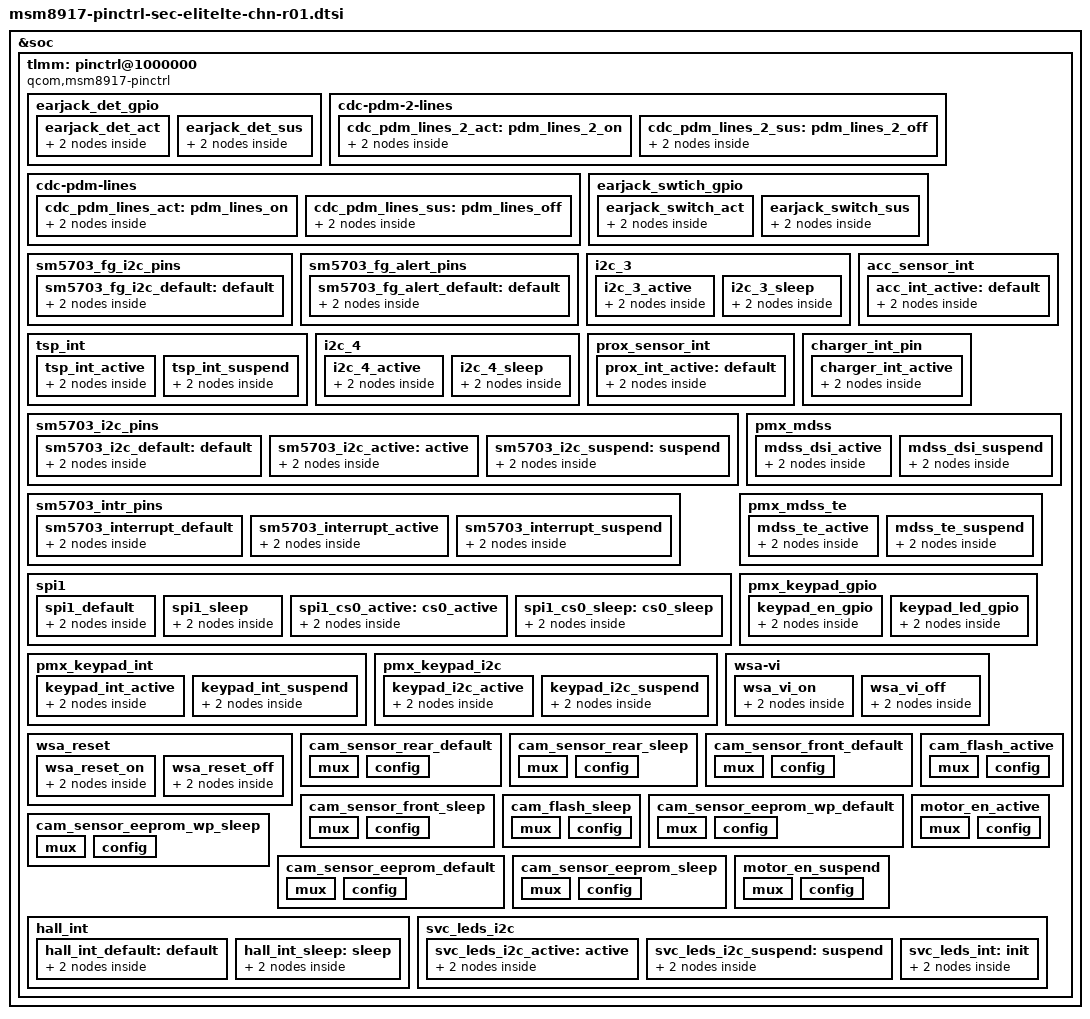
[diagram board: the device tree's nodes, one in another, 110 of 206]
/*
 * Copyright (c) 2015, The Linux Foundation. All rights reserved.
 *
 * This program is free software; you can redistribute it and/or modify
 * it under the terms of the GNU General Public License version 2 and
 * only version 2 as published by the Free Software Foundation.
 *
 * This program is distributed in the hope that it will be useful,
 * but WITHOUT ANY WARRANTY; without even the implied warranty of
 * MERCHANTABILITY or FITNESS FOR A PARTICULAR PURPOSE.  See the
 * GNU General Public License for more details.
 */

#include "../../qcom/msm8917-pinctrl.dtsi"

&soc {
	tlmm: pinctrl@1000000 {
		compatible = "qcom,msm8917-pinctrl";
		reg = <0x1000000 0x300000>;
		interrupts = <0 208 0>;
		gpio-controller;
		#gpio-cells = <2>;
		interrupt-controller;
		#interrupt-cells = <2>;

		earjack_det_gpio {
				earjack_det_act: earjack_det_act {
					mux {
						pins = "gpio61";
						function = "gpio";
					};

					config {
						pins = "gpio61";
						drive-strength = <2>;
						bias-disable;
					};
				};
				earjack_det_sus: earjack_det_sus {
					mux {
						pins = "gpio61";
						function = "gpio";
					};

					config {
						pins = "gpio61";
						drive-strength = <2>;
						bias-disable;
					};
				};
		};

		cdc-pdm-2-lines {
			cdc_pdm_lines_2_act: pdm_lines_2_on {
				mux {
					pins = "gpio70", "gpio71", "gpio72";
					function = "cdc_pdm0";
				};

				config {
					pins = "gpio70", "gpio71", "gpio72";
					drive-strength = <8>;
					bias-pull-down;
				};
			};

			cdc_pdm_lines_2_sus: pdm_lines_2_off {
				mux {
					pins = "gpio70", "gpio71", "gpio72";
					function = "cdc_pdm0";
				};

				config {
					pins = "gpio70", "gpio71", "gpio72";
					drive-strength = <2>;
					bias-pull-down;
				};
			};
		};

		cdc-pdm-lines {
			cdc_pdm_lines_act: pdm_lines_on {
				mux {
					pins = "gpio69", "gpio73", "gpio74";
					function = "cdc_pdm0";
				};

				config {
					pins = "gpio69", "gpio73", "gpio74";
					drive-strength = <8>;
					bias-pull-down;
				};
			};
			cdc_pdm_lines_sus: pdm_lines_off {
				mux {
					pins = "gpio69", "gpio73", "gpio74";
					function = "cdc_pdm0";
				};

				config {
					pins = "gpio69", "gpio73", "gpio74";
					drive-strength = <2>;
					bias-pull-down;
				};
			};
		};

		earjack_swtich_gpio {
				earjack_switch_act: earjack_switch_act {
					mux {
						pins = "gpio93";
						function = "gpio";
					};

					config {
						pins = "gpio93";
						drive-strength = <2>;
						bias-disable;
					};
				};
				earjack_switch_sus: earjack_switch_sus {
					mux {
						pins = "gpio93";
						function = "gpio";
					};

					config {
						pins = "gpio93";
						drive-strength = <2>;
						bias-disable;
					};
				};
		};


		/* Fuelgauge I2C pins */
		sm5703_fg_i2c_pins {

			sm5703_fg_i2c_default: default {
				/* default state */
				mux {
					pins = "gpio6", "gpio7";
					function = "gpio";
				};

				config {
					pins = "gpio6", "gpio7";
					drive-strength = <2>;
					bias-disable;
				};
			};

		};

		/* Fuelgauge alert pin */
                sm5703_fg_alert_pins {

                        sm5703_fg_alert_default: default {
                                /* default state */
                                mux {
                                        pins = "gpio63";
                                        function = "gpio";
                                };

                                config {
                                        pins = "gpio63";
                                        drive-strength = <2>;
                                        bias-disable;
                                };
                        };

                };

		/* pingrp for tsp - start */
		i2c_3 {
			i2c_3_active: i2c_3_active {
				/* active state */
				mux {
					pins = "gpio10", "gpio11";
					function = "blsp_i2c3";
				};

				config {
					pins = "gpio10", "gpio11";
					drive-strength = <2>;
					bias-disable;
				};
			};

			i2c_3_sleep: i2c_3_sleep {
				/* suspended state */
				mux {
					pins = "gpio10", "gpio11";
					function = "blsp_i2c3";
				};

				config {
					pins = "gpio10", "gpio11";
					drive-strength = <2>;
					bias-disable;
				};
			};
		};

		tsp_int {
			tsp_int_active: tsp_int_active {
				mux {
					pins = "gpio65";
					function = "gpio";
				};

				config {
					pins = "gpio65";
					drive-strength = <2>;
					bias-disable;
				};
			};
			tsp_int_suspend: tsp_int_suspend {
				mux {
					pins = "gpio65";
					function = "gpio";
				};

				config {
					pins = "gpio65";
					drive-strength = <2>;
					bias-disable;
				};
			};
		};

		/* pingrp for sensor - start */
		i2c_4 {
			i2c_4_active: i2c_4_active {
				/* active state */
				mux {
					pins = "gpio14", "gpio15";
					function = "blsp_i2c4";
				};

				config {
					pins = "gpio14", "gpio15";
					drive-strength = <2>;
					bias-disable;
				};
			};

			i2c_4_sleep: i2c_4_sleep {
				/* suspended state */
				mux {
					pins = "gpio14", "gpio15";
					function = "blsp_i2c4";
				};

				config {
					pins = "gpio14", "gpio15";
					drive-strength = <2>;
					bias-disable;
				};
			};
		};

		acc_sensor_int {
			acc_int_active: default {
				mux {
					pins = "gpio42";
					function = "gpio";
				};

				config {
					pins = "gpio42";
					drive-strength = <2>;
					bias-pull-down;
				};
			};
		};
		prox_sensor_int {
			prox_int_active: default {
				mux {
					pins = "gpio43";
					function = "gpio";
				};

				config {
					pins = "gpio43";
					drive-strength = <2>;
					bias-disable;
				};
			};
		};
		/* pingrp for sensor - end */

			/* MUIC - SM5703 */
		sm5703_i2c_pins {
			sm5703_i2c_default: default {
				/* default state*/
				mux {
					pins = "gpio16", "gpio17"; /* SDA, SCL */
                        		function = "gpio";
				};
				config {
					pins = "gpio16", "gpio17";
					drive-strength = <2>;
					bias-disable;
				};
			};
	
			sm5703_i2c_active: active {
				/*active state*/
				 mux {
                                        pins = "gpio16", "gpio17"; /* SDA, SCL */
                                        function = "gpio";
                                };
                                config {
                                        pins = "gpio16", "gpio17";
                                        drive-strength = <2>;
                                        bias-disable;
                                };
		
			};
			sm5703_i2c_suspend: suspend {
				/*suspend state*/
				 mux {
                                        pins = "gpio16", "gpio17"; /* SDA, SCL */
                                        function = "gpio";
                                };
                                config {
                                        pins = "gpio16", "gpio17";
                                        drive-strength = <2>;
                                        bias-disable;
                                };

			};
		};

		sm5703_intr_pins {
			sm5703_interrupt_default: sm5703_interrupt_default {
				/*default state*/
				mux {
					pins = "gpio28";
					function = "gpio";
				};
				config {
					pins = "gpio28";
					drive-strength = <2>;
					bias-disable;
				};
			};

			sm5703_interrupt_active: sm5703_interrupt_active {
				/*active state*/
				mux {
                                        pins = "gpio28";
                                        function = "gpio";
                                };
                                config {
                                        pins = "gpio28";
                                        drive-strength = <2>;
                                        bias-disable;
                                };
		
			};
			sm5703_interrupt_suspend: sm5703_interrupt_suspend {
				/*suspend state*/
				 mux {
                                        pins = "gpio28";
                                        function = "gpio";
                                };
                                config {
                                        pins = "gpio28";
                                        drive-strength = <2>;
                                        bias-disable;
                                };
			};
		};

		charger_int_pin {
			qcom,num-grp-pins = <1>;
			qcom,pin-func = <0>;
			label = "charger_int_gpio";
			charger_int_active: charger_int_active {
			    mux {
				    pins = "gpio35";
				    function = "gpio";
			    };
			    config {
				    pins = "gpio35";
				    drive-strength = <2>;
				    bias_disable;
			    };
		    };
		};

		spi1 {
			spi1_default: spi1_default {
				/* active state */
				mux {
					/* MOSI, MISO, CLK */
					pins = "gpio0", "gpio1", "gpio3";
					function = "blsp_spi1";
				};

				config {
					pins = "gpio0", "gpio1", "gpio3";
					drive-strength = <2>; /* 12 MA */
					bias-disable = <0>; /* No PULL */
					input-low;
				};
			};

			spi1_sleep: spi1_sleep {
				/* suspended state */
				mux {
					/* MOSI, MISO, CLK */
					pins = "gpio0", "gpio1", "gpio3";
					function = "gpio";
				};

				config {
					pins = "gpio0", "gpio1", "gpio3";
					drive-strength = <2>; /* 2 MA */
					bias-pull-down; /* PULL Down */
					input-low;
				};
			};

			spi1_cs0_active: cs0_active {
				/* CS */
				mux {
					pins = "gpio2";
					function = "blsp_spi1";
				};

				config {
					pins = "gpio2";
					drive-strength = <2>;
					bias-disable = <0>;
				};
			};

			spi1_cs0_sleep: cs0_sleep {
				/* CS */
				mux {
					pins = "gpio2";
					function = "gpio";
				};

				config {
					pins = "gpio2";
					drive-strength = <2>;
					bias-disable = <0>;
				};
			};
		};
		
		pmx_mdss: pmx_mdss {
			/* ON_CELL panel control LCD  power */
			mdss_dsi_active: mdss_dsi_active {
				mux {
					pins =
					/* LCD,BLIC */
					"gpio60", "gpio62", "gpio94", "gpio95";
					function = "gpio";
				};

				config {
					pins =
					/* LCD,BLIC */
					"gpio60", "gpio62", "gpio94", "gpio95";

					drive-strength = <8>; /* 8 mA */
					bias-pull-up; /* pull up */
					output-low;
				};
			};
			mdss_dsi_suspend: mdss_dsi_suspend {
				mux {
					pins =
					/* LCD,BLIC */
					"gpio60", "gpio62", "gpio94", "gpio95";
					function = "gpio";
				};

				config {
					pins =
					/* LCD,BLIC */
					"gpio60", "gpio62", "gpio94", "gpio95";

					drive-strength = <2>; /* 2 mA */
					bias-pull-down; /* pull down */
					input-enable;
				};
			};
		};

		pmx_mdss_te: pmx_mdss_te {
			mdss_te_active: mdss_te_active {
				mux {
					pins = "gpio24";
					function = "mdp_vsync";
				};
				config {
					pins = "gpio24";
					drive-strength = <2>; /* 8 mA */
					bias-pull-down; /* pull down*/
				};
			};

			mdss_te_suspend: mdss_te_suspend {
				mux {
					pins = "gpio24";
					function = "mdp_vsync";
				};
				config {
					pins = "gpio24";
					drive-strength = <2>; /* 2 mA */
					bias-pull-down; /* pull down */
				};
			};
		};

		/* add pingrp for keypad */
		pmx_keypad_gpio {
			keypad_en_gpio: keypad_en_gpio {
				mux {
					pins = "gpio24";
					function = "gpio";
				};

				config {
					pins = "gpio24";
					drive-strength = <2>;
					bias-disable;
				};
			};
			keypad_led_gpio: keypad_led_gpio {
				mux {
					pins = "gpio92";
					function = "gpio";
				};

				config {
					pins = "gpio92";
					drive-strength = <2>;
					bias-disable;
				};
			};
		};

		pmx_keypad_int {
			keypad_int_active: keypad_int_active {
				mux {
					pins = "gpio48";
					function = "gpio";
				};

				config {
					pins = "gpio48";
					drive-strength = <8>;
					bias-pull-up;
				};
			};
			keypad_int_suspend: keypad_int_suspend {
				mux {
					pins = "gpio48";
					function = "gpio";
				};

				config {
					pins = "gpio48";
					drive-strength = <2>;
				//	bias-pull-down;
					bias-disable; /* NO pull */
				};
			};
		};

		pmx_keypad_i2c {
			keypad_i2c_active: keypad_i2c_active {
				mux {
					pins = "gpio87",  "gpio88";
					function = "gpio";
				};

				config {
					pins = "gpio87",  "gpio88";
					drive-strength = <8>;
				//	bias-pull-up;
					bias-disable; /* NO pull */
				};
			};
			keypad_i2c_suspend: keypad_i2c_suspend {
				mux {
					pins = "gpio87",  "gpio88";
					function = "gpio";
				};

				config {
					pins = "gpio87",  "gpio88";
					drive-strength = <2>;
				//	bias-pull-down;
					bias-disable; /* NO pull */
				};
			};
		};

		/* WSA VI sense */
		wsa-vi {
			wsa_vi_on: wsa_vi_on {
				mux {
					/*pins = "gpio94", "gpio95";*/
					function = "wsa_io";
				};

				config {
					/*pins = "gpio94", "gpio95";*/
					drive-strength = <8>; /* 8 MA */
					bias-disable; /* NO pull */
				};
			};

			wsa_vi_off: wsa_vi_off {
				mux {
					/*pins = "gpio94", "gpio95";*/
					function = "wsa_io";
				};

				config {
					/*pins = "gpio94", "gpio95";*/
					drive-strength = <2>; /* 2 MA */
					bias-pull-down;
				};
			};
		};

		/* WSA Reset */
		wsa_reset {
			wsa_reset_on: wsa_reset_on {
				mux {
					/*pins = "gpio96";*/
					function = "gpio";
				};

				config {
					/*pins = "gpio96";*/
					drive-strength = <2>; /* 2 MA */
					output-high;
				};
			};

			wsa_reset_off: wsa_reset_off {
				mux {
					/*pins = "gpio96";*/
					function = "gpio";
				};

				config {
					/*pins = "gpio96";*/
					drive-strength = <2>; /* 2 MA */
					output-low;
				};
			};
		};

		cam_sensor_rear_default: cam_sensor_rear_default {
			/* RESET, STANDBY */
			mux {
				pins = "gpio36";
				function = "gpio";
			};

			config {
				pins = "gpio36";
				bias-disable; /* No PULL */
				drive-strength = <2>; /* 2 MA */
			};
		};

		cam_sensor_rear_sleep: cam_sensor_rear_sleep {
			/* RESET, STANDBY */
			mux {
				pins = "gpio36";
				function = "gpio";
			};

			config {
				pins = "gpio36";
				bias-disable; /* No PULL */
				drive-strength = <2>; /* 2 MA */
			};
		};

		cam_sensor_front_default: cam_sensor_front_default {
			/* RESET, STANDBY */
			mux {
				pins = "gpio38";
				function = "gpio";
			};

			config {
				pins = "gpio38";
				bias-disable; /* No PULL */
				drive-strength = <2>; /* 2 MA */
			};
		};

		cam_sensor_front_sleep: cam_sensor_front_sleep {
			/* RESET, STANDBY */
			mux {
				pins = "gpio38";
				function = "gpio";
			};

			config {
				pins = "gpio38";
				bias-disable; /* No PULL */
				drive-strength = <2>; /* 2 MA */
			};
		};

		cam_flash_active: cam_flash_active {
			/* TORCH, FLASH */
			mux {
				pins = "gpio34", "gpio33";
				function = "gpio";
			};

			config {
				pins = "gpio34", "gpio33";
				bias-pull-down; /* PULL DOWN */
				drive-strength = <2>; /* 2 MA */
				output-low;
			};
		};

		cam_flash_sleep: cam_flash_sleep {
			/* TORCH, FLASH */
			mux {
				pins = "gpio34", "gpio33";
				function = "gpio";
			};

			config {
				pins = "gpio34", "gpio33";
				bias-pull-down; /* PULL DOWN */
				drive-strength = <2>; /* 2 MA */
				output-low;
			};
		};


		cam_sensor_eeprom_wp_default: cam_sensor_eeprom_wp_default {
			mux {
				pins = "gpio85";
				function = "gpio";
			};

			config {
				pins = "gpio85";
				bias-disable;
				drive-strength = <4>;
				output-low;
			};
		};

		cam_sensor_eeprom_wp_sleep: cam_sensor_eeprom_wp_sleep {
			mux {
				pins = "gpio85";
				function = "gpio";
			};

			config {
				pins = "gpio85";
				bias-pull-down;
				drive-strength = <4>;
				output-low;
			};
		};

		cam_sensor_eeprom_default: cam_sensor_eeprom_default {
			mux {
				pins = "gpio22", "gpio23";
				function = "gpio";
			};

			config {
				pins = "gpio22", "gpio23";
				bias-disable;
				drive-strength = <4>;
				output-low;
			};
		};

		cam_sensor_eeprom_sleep: cam_sensor_eeprom_sleep {
			mux {
				pins = "gpio22", "gpio23";
				function = "gpio";
			};

			config {
				pins = "gpio22", "gpio23";
				bias-pull-down;
				drive-strength = <4>;
				output-low;
			};
		};

		/* add pinctrl for motor  */
		motor_en_active: motor_en_active {
			mux {
				pins = "gpio40";
				function = "gpio";
			};

			config {
				pins = "gpio40";
				bias-pull-down;
				drive-strength = <2>;
				output-high;
			};
		};

		motor_en_suspend: motor_en_suspend {
			mux {
				pins = "gpio40";
				function = "gpio";
			};

			config {
				pins = "gpio40";
				bias-pull-down;
				drive-strength = <2>;
				output-low;
			};
		};

		hall_int {
			hall_int_default: default {
				mux {
					pins = "gpio97";
					function = "gpio";
				};

				config {
					pins = "gpio97";
					bias-disable;
					drive-strength = <2>;
				};
        		};

			hall_int_sleep: sleep {
				mux {
					pins = "gpio97";
					function = "gpio";
				};

				config {
					pins = "gpio97";
					bias-disable;
					drive-strength = <2>;
				};
        		};
		};

		svc_leds_i2c {
			svc_leds_i2c_active: active {
				mux {
					pins = "gpio12" , "gpio13"; /* SDA, SCL */
					function = "NA";
				};

				config {
					pins = "gpio12", "gpio13";
					bias-disable;
					drive-strength = <2>;
				};
			};

			svc_leds_i2c_suspend: suspend {
				mux {
					pins = "gpio12" , "gpio13"; /* SDA, SCL */
					function = "NA";
				};

				config {
					pins = "gpio12", "gpio13";
					bias-disable;
					drive-strength = <2>;
				};
			};
			
			svc_leds_int: init {
				mux {
					pins = "gpio8";
					function = "gpio";
				};

				config {
					pins = "gpio8";
					bias-disable;
					drive-strength = <2>;
				};
        		};
			
			
		};
	};
};
